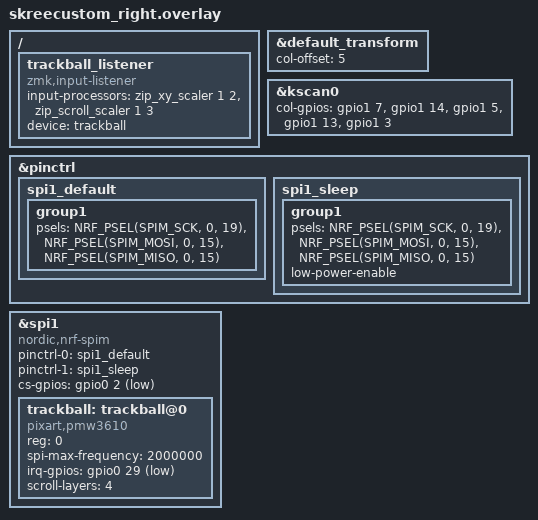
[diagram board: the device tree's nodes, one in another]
#include "skreecustom.dtsi"

#include <input/processors.dtsi>

 &default_transform {
    col-offset = <5>;
};

&kscan0 {
    col-gpios           // Col1-7 1.07 1.14 1.05 1.13 1.03 1.12 0.16 
        = <&gpio1 7 GPIO_ACTIVE_HIGH> 
        , <&gpio1 14 GPIO_ACTIVE_HIGH>
        , <&gpio1 5 GPIO_ACTIVE_HIGH>
        , <&gpio1 13 GPIO_ACTIVE_HIGH> 
        , <&gpio1 3 GPIO_ACTIVE_HIGH> 
//      , <&gpio1 12 GPIO_ACTIVE_HIGH> 
//      , <&gpio0 16 GPIO_ACTIVE_HIGH> 
        ;
};

&pinctrl {
    spi1_default: spi1_default {
        group1 {
            psels = <NRF_PSEL(SPIM_SCK, 0, 19)>,
                <NRF_PSEL(SPIM_MOSI, 0, 15)>,
                <NRF_PSEL(SPIM_MISO, 0, 15)>;
        };
    };
    spi1_sleep: spi1_sleep {
        group1 {
            psels = <NRF_PSEL(SPIM_SCK, 0, 19)>,
                <NRF_PSEL(SPIM_MOSI, 0, 15)>,
                <NRF_PSEL(SPIM_MISO, 0, 15)>;
            low-power-enable;
        };
    };
};
&spi1 {
    status = "okay";
    compatible = "nordic,nrf-spim";
    pinctrl-0 = <&spi1_default>;
    pinctrl-1 = <&spi1_sleep>;
    pinctrl-names = "default", "sleep";
    cs-gpios = <&gpio0 2 GPIO_ACTIVE_LOW>; 
    trackball: trackball@0 {
        status = "okay";
        compatible = "pixart,pmw3610";
        reg = <0>;
        spi-max-frequency = <2000000>;
        irq-gpios = <&gpio0 29 (GPIO_ACTIVE_LOW | GPIO_PULL_UP)>; 
        scroll-layers = <4>;
    };
};
/ {
  trackball_listener {
    compatible = "zmk,input-listener";
    input-processors = <&zip_xy_scaler 1 2>, <&zip_scroll_scaler 1 3>;
    device = <&trackball>;
  };
};
